AUTOSAR XML (schema 4-3-0)
standard types defined: uint16, uint32, uint8, uint16_DataConstr, uint32_DataConstr, uint8_DataConstr, sint16, boolean, sint32
package /ASP_DataTypes
  48 x impl type:
    accPedalPosition: category=VALUE, base-type=BaseTypes/uint8
    accPedalPositionQual: category=VALUE, base-type=BaseTypes/uint8, compu {0=Cx0_Unsafe, 1=Cx1_Safe, 2=Cx2_SNA; unit Enum}
    brakePedalPressed: category=VALUE, base-type=boolean, compu {0=Cx0_No, 1=Cx1_Yes; unit Enum}
    brakePedalPressedQual: category=VALUE, base-type=BaseTypes/uint8, compu {0=Cx0_Unsafe, 1=Cx1_Safe, 2=Cx2_SNA; unit Enum}
    brakeTorque: category=VALUE, base-type=BaseTypes/uint16
    collAvoidSnvtySetting: category=VALUE, base-type=BaseTypes/uint8, compu {0=Cx0_NotInUse, 1=Cx1_LoSnvty, 2=Cx2_NormSnvty, 3=Cx3_HiSnvty; unit Enum}
    collAvoidSnvtySettingQual: category=VALUE, base-type=BaseTypes/uint8, compu {0=Cx0_Unsafe, 1=Cx1_Safe, 2=Cx2_SNA; unit Enum}
    driverAEBOverride: category=VALUE, base-type=boolean, compu {0=Cx0_No, 1=Cx1_Yes; unit Enum}
    driverAEBOverrideQual: category=VALUE, base-type=BaseTypes/uint8, compu {0=Cx0_Unsafe, 1=Cx1_Safe, 2=Cx2_SNA; unit Enum}
    driverBrakeTorque: category=VALUE, base-type=BaseTypes/uint16
    driverBrakeTorqueQual: category=VALUE, base-type=BaseTypes/uint8, compu {0=Cx0_Unsafe, 1=Cx1_Safe, 2=Cx2_SNA; unit Enum}
    dynamicWheelRadiusFront: category=VALUE, base-type=BaseTypes/uint16
    dynamicWheelRadiusRear: category=VALUE, base-type=BaseTypes/uint16
    EgoMotion_rec: category=STRUCTURE
      20 x element, all with category=TYPE_REFERENCE:
        dynamicWheelRadiusRear: range raw 0..4095, implementation-data-type=dynamicWheelRadiusRear
        lateralAccelerationQual: range raw 0..3, implementation-data-type=lateralAccelerationQual
        lateralAcceleration: range raw -2048..2047, implementation-data-type=lateralAcceleration
        longitudinalSpeedQual: range raw 0..3, implementation-data-type=longitudinalSpeedQual
        wheelSpeedFrontRight: range raw -8192..8191, implementation-data-type=wheelSpeedFrontRight
        dynamicWheelRadiusFront: range raw 0..4095, implementation-data-type=dynamicWheelRadiusFront
        wheelSpeedQual: range raw 0..3, implementation-data-type=wheelSpeedQual
        wheelSpeedFrontLeft: range raw -8192..8191, implementation-data-type=wheelSpeedFrontLeft
        longitudinalSpeed: range raw -8192..8191, implementation-data-type=longitudinalSpeed
        rearWheelAngleQual: range raw 0..3, implementation-data-type=rearWheelAngleQual
        wheelSpeedRearRight: range raw -8192..8191, implementation-data-type=wheelSpeedRearRight
        longitudinalAccelerationQual: range raw 0..3, implementation-data-type=longitudinalAccelerationQual
        frontWheelAngle: range raw -16384..16383, implementation-data-type=frontWheelAngle
        rearWheelAngle: range raw -16384..16383, implementation-data-type=rearWheelAngle
        wheelSpeedRearLeft: range raw -8192..8191, implementation-data-type=wheelSpeedRearLeft
        frontWheelAngleQual: range raw 0..3, implementation-data-type=frontWheelAngleQual
        longitudinalAcceleration: range raw -2048..2047, implementation-data-type=longitudinalAcceleration
        yawRate: implementation-data-type=yawRate
        yawRateQual: range raw 0..3, implementation-data-type=yawRateQual
        brakeTorque: range raw 0..16383, implementation-data-type=brakeTorque
    engineState: category=VALUE, base-type=BaseTypes/uint8, compu {0=Cx0_Stop, 1=Cx1_Start, 2=Cx2_Idle_Unstable (Idle Unstable), 3=Cx3_Idle_Stable (Idle Stable), 4=Cx4_Unlimited, 5=Cx5_Limited, 6=Cx6_SNA; unit Enum}
    frontWheelAngle: category=VALUE, base-type=BaseTypes/sint16
    frontWheelAngleQual: category=VALUE, base-type=BaseTypes/uint8, compu {0=Cx0_Unavailable, 1=Cx1_Available, 2=Cx2_SNA; unit Enum}
    ignitionState: category=VALUE, base-type=BaseTypes/uint8, compu {0=Cx0_Lock, 1=Cx1_OFF, 2=Cx2_ACC, 3=Cx3_ON, 4=Cx4_Start, 5=Cx5_SNA; unit Enum}
    lateralAcceleration: category=VALUE, base-type=BaseTypes/sint16
    lateralAccelerationQual: category=VALUE, base-type=BaseTypes/uint8, compu {0=Cx0_Unavailable, 1=Cx1_Available, 2=Cx2_SNA; unit Enum}
    lateralAccRaw: category=VALUE, base-type=BaseTypes/sint16
    lateralAccRawQual: category=VALUE, base-type=BaseTypes/uint8, compu {0=Cx0_Unsafe, 1=Cx1_Safe, 2=Cx2_SNA; unit Enum}
    longitudinalAcceleration: category=VALUE, base-type=BaseTypes/sint16
    longitudinalAccelerationQual: category=VALUE, base-type=BaseTypes/uint8, compu {0=Cx0_Unavailable, 1=Cx1_Available, 2=Cx2_SNA; unit Enum}
    longitudinalAccRaw: category=VALUE, base-type=BaseTypes/sint16
    longitudinalAccRawQual: category=VALUE, base-type=BaseTypes/uint8, compu {0=Cx0_Unsafe, 1=Cx1_Safe, 2=Cx2_SNA; unit Enum}
    longitudinalSpeed: category=VALUE, base-type=BaseTypes/sint16
    longitudinalSpeedQual: category=VALUE, base-type=BaseTypes/uint8, compu {0=Cx0_Unsafe, 1=Cx1_Safe, 2=Cx2_SNA; unit Enum}
    PositionInfoType: category=STRUCTURE, sw-calibration-access=READ-ONLY, type-emitter=RTE
      element countryCode: category=VALUE, base-type=BaseTypes/uint16, sw-calibration-access=READ-ONLY, invalid-value=1023  # Current country in ISO 3166-1 numerical
    rearWheelAngle: category=VALUE, base-type=BaseTypes/sint16
    rearWheelAngleQual: category=VALUE, base-type=BaseTypes/uint8, compu {0=Cx0_Unavailable, 1=Cx1_Available, 2=Cx2_SNA; unit Enum}
    SG_AEB_Input: category=STRUCTURE
      20 x element, all with category=TYPE_REFERENCE:
        longitudinalAccRaw: range raw -16384..16383, implementation-data-type=longitudinalAccRaw
        steeringWhlAngleSpeedQual: range raw 0..3, implementation-data-type=steeringWhlAngleSpeedQual
        lateralAccRawQual: range raw 0..3, implementation-data-type=lateralAccRawQual
        brakePedalPressed: implementation-data-type=brakePedalPressed
        vehicleMotionState: range raw 0..7, implementation-data-type=vehicleMotionState
        driverBrakeTorqueQual: range raw 0..3, implementation-data-type=driverBrakeTorqueQual
        steeringWhlAngle: range raw -16384..16383, implementation-data-type=steeringWhlAngle
        steeringWhlAngleQual: range raw 0..3, implementation-data-type=steeringWhlAngleQual
        accPedalPositionQual: range raw 0..3, implementation-data-type=accPedalPositionQual
        collAvoidSnvtySetting: range raw 0..3, implementation-data-type=collAvoidSnvtySetting
        longitudinalAccRawQual: range raw 0..3, implementation-data-type=longitudinalAccRawQual
        steeringWhlAngleSpeed: range raw -65536..65535, implementation-data-type=steeringWhlAngleSpeed
        driverAEBOverrideQual: range raw 0..3, implementation-data-type=driverAEBOverrideQual
        collAvoidSnvtySettingQual: range raw 0..3, implementation-data-type=collAvoidSnvtySettingQual
        driverAEBOverride: implementation-data-type=driverAEBOverride
        accPedalPosition: range raw 0..100, implementation-data-type=accPedalPosition
        vehicleMotionStateQual: range raw 0..3, implementation-data-type=vehicleMotionStateQual
        driverBrakeTorque: range raw 0..20000, implementation-data-type=driverBrakeTorque
        brakePedalPressedQual: range raw 0..3, implementation-data-type=brakePedalPressedQual
        lateralAccRaw: range raw -16384..16383, implementation-data-type=lateralAccRaw
    steeringWhlAngle: category=VALUE, base-type=BaseTypes/sint16
    steeringWhlAngleQual: category=VALUE, base-type=BaseTypes/uint8, compu {0=Cx0_Unsafe, 1=Cx1_Safe, 2=Cx2_SNA; unit Enum}
    steeringWhlAngleSpeed: category=VALUE, base-type=sint32
    steeringWhlAngleSpeedQual: category=VALUE, base-type=BaseTypes/uint8, compu {0=Cx0_Unsafe, 1=Cx1_Safe, 2=Cx2_SNA; unit Enum}
    suspensionType: category=VALUE, base-type=BaseTypes/uint8
    turnIndicator: category=VALUE, base-type=BaseTypes/uint8
    VehicleMisc_rec: category=STRUCTURE
      4 x element, all with category=TYPE_REFERENCE, range raw 0..7:
        suspensionType: implementation-data-type=suspensionType
        ignitionState: implementation-data-type=ignitionState
        turnIndicator: implementation-data-type=turnIndicator
        engineState: implementation-data-type=engineState
    vehicleMotionState: category=VALUE, base-type=BaseTypes/uint8, compu {0=Cx0_Ukwn, 1=Cx1_StandStillVal1, 2=Cx2_StandStillVal2, 3=Cx3_StandStillVal3, 4=Cx4_RollgFwdVal1, 5=Cx5_RollgFwdVal2, 6=Cx6_RollgBackwVal1, 7=Cx7_RollgBackwVal2; unit Enum}
    vehicleMotionStateQual: category=VALUE, base-type=BaseTypes/uint8, compu {0=Cx0_Unsafe, 1=Cx1_Safe, 2=Cx2_SNA; unit Enum}
    wheelSpeedFrontLeft: category=VALUE, base-type=BaseTypes/sint16
    wheelSpeedFrontRight: category=VALUE, base-type=BaseTypes/sint16
    wheelSpeedQual: category=VALUE, base-type=BaseTypes/uint8, compu {0=Cx0_Unavailable, 1=Cx1_Available, 2=Cx2_SNA; unit Enum}
    wheelSpeedRearLeft: category=VALUE, base-type=BaseTypes/sint16
    wheelSpeedRearRight: category=VALUE, base-type=BaseTypes/sint16
    yawRate: category=VALUE, base-type=BaseTypes/sint16
    yawRateQual: category=VALUE, base-type=BaseTypes/uint8, compu {0=Cx0_Unavailable, 1=Cx1_Available, 2=Cx2_SNA; unit Enum}
package /ASP_DataTypes/Units
  unit U_Enum: display-name=Enum, factor-si-to-unit=1, offset-si-to-unit=0
package /ASP_PortInterfaces
  sender receiver interface CddGvpSRVehicleInputInterface
    data EgoMotionElement: type=EgoMotion_rec
    data PositionInfo: type=PositionInfoType
    data VehicleMiscElement: type=VehicleMisc_rec
    invalidation-policys:
      data-element=EgoMotionElement, handle-invalid=DONT-INVALIDATE
      data-element=VehicleMiscElement, handle-invalid=DONT-INVALIDATE
      data-element=PositionInfo, handle-invalid=DONT-INVALIDATE
  sender receiver interface SG_AEB_Input: invalidation-policy{data-element=SG_AEB_Input, handle-invalid=DONT-INVALIDATE}
    data SG_AEB_Input: type=SG_AEB_Input
package /ComponentTypes/HkmcRadarAdapSWC/Constants
  constant specification CS_RadarAdap_Radar: value-spec=fields=[SAS_AnglVal:0, ESC_YawRtVal:0, ESC_LatAccelVal:0, ESC_LongAccelVal:0, longitudinalSpeed:0, longitudinalSpeedQual:0, WHL_DirFLVal:0, WHL_DirFRVal:0, WHL_DirRLVal:0, WHL_DirRRVal:0, ENG_EngSta:0, HCU_HevRdySta:0, VCU_EVRdySta:0, ENG_IgnOnSta:0, CLU_OdoVal:0]
package /ComponentTypes/HkmcRadarAdapSWC/DataTypes
  impl type Radar_T: category=STRUCTURE, sw-calibration-access=READ-ONLY, type-emitter=RTE
    15 x element, all with category=TYPE_REFERENCE:
      SAS_AnglVal: implementation-data-type=uint8
      ESC_YawRtVal: implementation-data-type=uint8
      ESC_LatAccelVal: implementation-data-type=uint8
      ESC_LongAccelVal: implementation-data-type=uint16
      longitudinalSpeed: implementation-data-type=uint8
      longitudinalSpeedQual: implementation-data-type=uint8
      WHL_DirFLVal: implementation-data-type=uint8
      WHL_DirFRVal: implementation-data-type=uint8
      WHL_DirRLVal: implementation-data-type=uint8
      WHL_DirRRVal: implementation-data-type=uint8
      ENG_EngSta: implementation-data-type=uint8
      HCU_HevRdySta: implementation-data-type=uint8
      VCU_EVRdySta: implementation-data-type=uint8
      ENG_IgnOnSta: implementation-data-type=uint8
      CLU_OdoVal: implementation-data-type=uint32
package /ComponentTypes/HkmcRadarAdapSWC/PortInterfaces
  sender receiver interface IF_Radar: invalidation-policy{data-element=DE_HkmcRadarAdapInput, handle-invalid=DONT-INVALIDATE}
    data DE_HkmcRadarAdapInput: type=Radar_T
package /ComponentTypes/HkmcVehicleInputSWC
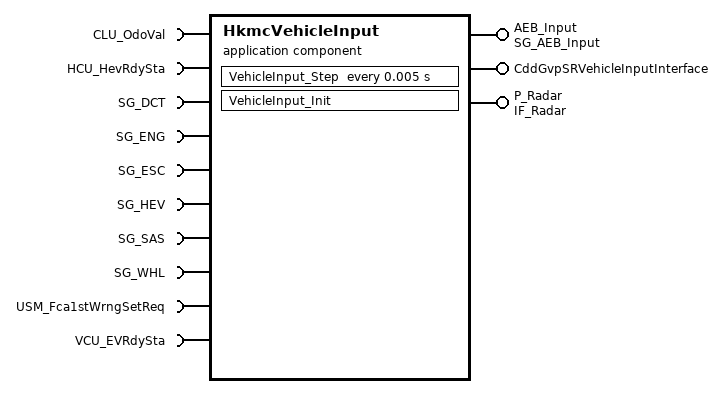
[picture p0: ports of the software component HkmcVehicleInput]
  application sw component type HkmcVehicleInput
    provide port AEB_Input: nonqueued-sender-com-spec{data-element=SG_AEB_Input, init-value=fields=[longitudinalAccRaw:0, steeringWhlAngleSpeedQual:0, lateralAccRawQual:0, brakePedalPressed:0, vehicleMotionState:0, driverBrakeTorqueQual:0, steeringWhlAngle:0, steeringWhlAngleQual:0, accPedalPositionQual:0, collAvoidSnvtySetting:0, longitudinalAccRawQual:0, steeringWhlAngleSpeed:0, driverAEBOverrideQual:0, collAvoidSnvtySettingQual:0, driverAEBOverride:0, accPedalPosition:0, vehicleMotionStateQual:0, driverBrakeTorque:0, brakePedalPressedQual:0, lateralAccRaw:0]}, provided-interface=SG_AEB_Input
    provide port CddGvpSRVehicleInputInterface: provided-com-specs=[data-element=EgoMotionElement, data-element=PositionInfo, data-element=VehicleMiscElement], provided-interface=CddGvpSRVehicleInputInterface
    provide port P_Radar: nonqueued-sender-com-spec{data-element=DE_HkmcRadarAdapInput, init-value=constant-reference=CS_RadarAdap_Radar}, provided-interface=IF_Radar
    10 x require port:
      CLU_OdoVal: nonqueued-receiver-com-spec{data-element=CLU_OdoVal, filter=data-filter-type=ALWAYS, init-value=0}, required-interface=CLU_OdoVal
      HCU_HevRdySta: nonqueued-receiver-com-spec{data-element=HCU_HevRdySta, filter=data-filter-type=ALWAYS, init-value=0}, required-interface=HCU_HevRdySta
      SG_DCT: nonqueued-receiver-com-spec{data-element=SG_DCT, filter=data-filter-type=ALWAYS, init-value=fields=DCT_AccelPdlVal:0}, required-interface=SG_DCT
      SG_ENG: nonqueued-receiver-com-spec{data-element=SG_ENG, filter=data-filter-type=ALWAYS, init-value=fields=ENG_IgnOnSta:1}, required-interface=SG_ENG
      SG_ESC: nonqueued-receiver-com-spec{data-element=SG_ESC, filter=data-filter-type=ALWAYS, init-value=fields=[ESC_LatAccelSigSta:2, ESC_LatAccelVal:32768, ESC_LongAccelSigSta:2, ESC_LongAccelVal:32768, ESC_YawRtVal:32768, ESC_YawSigSta:2]}, required-interface=SG_ESC
      SG_HEV: nonqueued-receiver-com-spec{data-element=SG_HEV, filter=data-filter-type=ALWAYS, init-value=fields=[HEV_AccelPdlVal:0, HEV_EngSpdVal:0]}, required-interface=SG_HEV
      SG_SAS: nonqueued-receiver-com-spec{data-element=SG_SAS, filter=data-filter-type=ALWAYS, init-value=fields=[SAS_AlvCnt1Val:0, SAS_AnglVal:0, SAS_Crc1Val:65535, SAS_IntSta:7, SAS_SpdVal:0]}, required-interface=SG_SAS
      SG_WHL: nonqueued-receiver-com-spec{data-element=SG_WHL, filter=data-filter-type=ALWAYS, init-value=fields=[WHL_DirRRVal:0, WHL_SpdFLVal:0, WHL_SpdFRVal:0, WHL_SpdRLVal:0, WHL_SpdRRVal:0]}, required-interface=SG_WHL
      USM_Fca1stWrngSetReq: nonqueued-receiver-com-spec{data-element=USM_Fca1stWrngSetReq, filter=data-filter-type=ALWAYS, init-value=0}, required-interface=USM_Fca1stWrngSetReq
      VCU_EVRdySta: nonqueued-receiver-com-spec{data-element=VCU_EVRdySta, filter=data-filter-type=ALWAYS, init-value=0}, required-interface=VCU_EVRdySta
    behavior HkmcVehicleInput_InternalBehavior
      init event VehicleInput_InitEvent: start-on-event=VehicleInput_Init
      timing event VehicleInput_Step_TE: start-on-event=VehicleInput_Step, period=0.005
      runnable VehicleInput_Init
        data-receive-point-by-arguments:
          10 x access:
            REC_CLU_OdoVal_CLU_OdoVal: accessed-variable=CLU_OdoVal.CLU_OdoVal
            REC_HCU_HevRdySta_HCU_HevRdySta: accessed-variable=HCU_HevRdySta.HCU_HevRdySta
            REC_SG_DCT_SG_DCT: accessed-variable=SG_DCT.SG_DCT
            REC_SG_ENG_SG_ENG: accessed-variable=SG_ENG.SG_ENG
            REC_SG_ESC_SG_ESC: accessed-variable=SG_ESC.SG_ESC
            REC_SG_HEV_SG_HEV: accessed-variable=SG_HEV.SG_HEV
            REC_SG_SAS_SG_SAS: accessed-variable=SG_SAS.SG_SAS
            REC_SG_WHL_SG_WHL: accessed-variable=SG_WHL.SG_WHL
            REC_USM_Fca1stWrngSetReq_USM_Fca1stWrngSetReq: accessed-variable=USM_Fca1stWrngSetReq.USM_Fca1stWrngSetReq
            REC_VCU_EVRdySta_VCU_EVRdySta: accessed-variable=VCU_EVRdySta.VCU_EVRdySta
        data-send-points:
          5 x access:
            SEND_AEB_Input_SG_AEB_Input: accessed-variable=AEB_Input.SG_AEB_Input
            SEND_CddGvpSRVehicleInputInterface_EgoMotionElement: accessed-variable=CddGvpSRVehicleInputInterface.EgoMotionElement
            SEND_CddGvpSRVehicleInputInterface_PositionInfo: accessed-variable=CddGvpSRVehicleInputInterface.PositionInfo
            SEND_CddGvpSRVehicleInputInterface_VehicleMiscElement: accessed-variable=CddGvpSRVehicleInputInterface.VehicleMiscElement
            SEND_P_Radar_DE_HkmcRadarAdapInput: accessed-variable=P_Radar.DE_HkmcRadarAdapInput
      runnable VehicleInput_Step
        data-receive-point-by-arguments:
          10 x access:
            REC_CLU_OdoVal_CLU_OdoVal: accessed-variable=CLU_OdoVal.CLU_OdoVal
            REC_HCU_HevRdySta_HCU_HevRdySta: accessed-variable=HCU_HevRdySta.HCU_HevRdySta
            REC_SG_DCT_SG_DCT: accessed-variable=SG_DCT.SG_DCT
            REC_SG_ENG_SG_ENG: accessed-variable=SG_ENG.SG_ENG
            REC_SG_ESC_SG_ESC: accessed-variable=SG_ESC.SG_ESC
            REC_SG_HEV_SG_HEV: accessed-variable=SG_HEV.SG_HEV
            REC_SG_SAS_SG_SAS: accessed-variable=SG_SAS.SG_SAS
            REC_SG_WHL_SG_WHL: accessed-variable=SG_WHL.SG_WHL
            REC_USM_Fca1stWrngSetReq_USM_Fca1stWrngSetReq: accessed-variable=USM_Fca1stWrngSetReq.USM_Fca1stWrngSetReq
            REC_VCU_EVRdySta_VCU_EVRdySta: accessed-variable=VCU_EVRdySta.VCU_EVRdySta
        data-send-points:
          5 x access:
            SEND_AEB_Input_SG_AEB_Input: accessed-variable=AEB_Input.SG_AEB_Input
            SEND_CddGvpSRVehicleInputInterface_EgoMotionElement: accessed-variable=CddGvpSRVehicleInputInterface.EgoMotionElement
            SEND_CddGvpSRVehicleInputInterface_PositionInfo: accessed-variable=CddGvpSRVehicleInputInterface.PositionInfo
            SEND_CddGvpSRVehicleInputInterface_VehicleMiscElement: accessed-variable=CddGvpSRVehicleInputInterface.VehicleMiscElement
            SEND_P_Radar_DE_HkmcRadarAdapInput: accessed-variable=P_Radar.DE_HkmcRadarAdapInput
  swc implementation HkmcVehicleInput_Implementation: behavior=HkmcVehicleInput_InternalBehavior
    code-descriptors:
      code Default: artifact-descriptors=autosar-engineering-object={short-label=Default, category=SWSRC}
package /DataTypes
  30 x impl type:
    CLU_OdoVal: category=VALUE, base-type=DataType/uint32, range raw 0..16777215
    DCT_AccelPdlVal: category=VALUE, base-type=DataType/uint16
    ENG_IgnOnSta: category=VALUE, base-type=DataType/uint8, compu {0=Cx0_KEY_OFF_control_unit_in_self_holding_phase (KEY OFF, control unit in self-holding phase), 1=Cx1_KEY_ON (KEY ON), 2=Cx2_Not_used (Not used), 3=Cx3_Error_indicator (Error indicator)}
    ESC_LatAccelSigSta: category=VALUE, base-type=DataType/uint8
    ESC_LatAccelVal: category=VALUE, base-type=DataType/uint16
    ESC_LongAccelSigSta: category=VALUE, base-type=DataType/uint8
    ESC_LongAccelVal: category=VALUE, base-type=DataType/uint16
    ESC_YawRtVal: category=VALUE, base-type=DataType/uint16
    ESC_YawSigSta: category=VALUE, base-type=DataType/uint8
    HCU_HevRdySta: category=VALUE, base-type=DataType/uint8, compu {0=Cx0_HEV_not_ready (HEV not ready), 1=Cx1_HEV_Drivable (HEV Drivable), 2=Cx2_Not_used (Not used), 3=Cx3_Error_Indicator (Error Indicator)}, range raw 0..3
    HEV_AccelPdlVal: category=VALUE, base-type=DataType/uint16
    HEV_EngSpdVal: category=VALUE, base-type=DataType/uint16
    SAS_AlvCnt1Val: category=VALUE, base-type=DataType/uint8
    SAS_AnglVal: category=VALUE, base-type=DataType/sint16
    SAS_Crc1Val: category=VALUE, base-type=DataType/uint16
    SAS_IntSta: category=VALUE, base-type=DataType/uint8
    SAS_SpdVal: category=VALUE, base-type=DataType/uint8
    SG_DCT: category=STRUCTURE
      element DCT_AccelPdlVal: range raw 0..1023, implementation-data-type=DCT_AccelPdlVal
    SG_ENG: category=STRUCTURE
      element ENG_IgnOnSta: range raw 0..3, implementation-data-type=ENG_IgnOnSta
    SG_ESC: category=STRUCTURE
      6 x element, all with category=TYPE_REFERENCE:
        ESC_LatAccelSigSta: range raw 0..15, implementation-data-type=ESC_LatAccelSigSta
        ESC_LatAccelVal: implementation-data-type=ESC_LatAccelVal
        ESC_LongAccelSigSta: range raw 0..15, implementation-data-type=ESC_LongAccelSigSta
        ESC_LongAccelVal: implementation-data-type=ESC_LongAccelVal
        ESC_YawRtVal: implementation-data-type=ESC_YawRtVal
        ESC_YawSigSta: range raw 0..15, implementation-data-type=ESC_YawSigSta
    SG_HEV: category=STRUCTURE
      element HEV_AccelPdlVal: range raw 0..1023, implementation-data-type=HEV_AccelPdlVal
      element HEV_EngSpdVal: implementation-data-type=HEV_EngSpdVal
    SG_SAS: category=STRUCTURE
      5 x element, all with category=TYPE_REFERENCE:
        SAS_AlvCnt1Val: range raw 0..255, implementation-data-type=SAS_AlvCnt1Val
        SAS_AnglVal: implementation-data-type=SAS_AnglVal
        SAS_Crc1Val: range raw 0..65535, implementation-data-type=SAS_Crc1Val
        SAS_IntSta: range raw 0..255, implementation-data-type=SAS_IntSta
        SAS_SpdVal: implementation-data-type=SAS_SpdVal
    SG_WHL: category=STRUCTURE
      5 x element, all with category=TYPE_REFERENCE:
        WHL_DirRRVal: range raw 0..3, implementation-data-type=WHL_DirRRVal
        WHL_SpdFLVal: range raw 0..16383, implementation-data-type=WHL_SpdFLVal
        WHL_SpdFRVal: range raw 0..16383, implementation-data-type=WHL_SpdFRVal
        WHL_SpdRLVal: range raw 0..16383, implementation-data-type=WHL_SpdRLVal
        WHL_SpdRRVal: range raw 0..16383, implementation-data-type=WHL_SpdRRVal
    USM_Fca1stWrngSetReq: category=VALUE, base-type=DataType/uint8, compu {0=Cx0_Default, 1=Cx1_On_Late_ (On (Late)), 2=Cx2_ON_Normal_ (ON (Normal)), 3=Cx3_ON_Early_ (ON (Early)), 4=Cx4_Reserved, 5=Cx5_Reserved, 6=Cx6_Reserved, 7=Cx7_Invalid}, range raw 0..7
    VCU_EVRdySta: category=VALUE, base-type=DataType/uint8, compu {0=Cx0_None, 1=Cx1_EV_Drivable (EV Drivable), 2=Cx2_Not_used (Not used), 3=Cx3_Error_Indicator (Error Indicator)}, range raw 0..3
    WHL_DirRRVal: category=VALUE, base-type=DataType/uint8, compu {0=Cx0_Unknown_Wheel_moving_stop_state_or_Not_applied_wheel_sensor_for_direction_ (Unknown (Wheel moving stop state or Not applied wheel sensor for direction)), 1=Cx1_Forward_direction (Forward direction), 2=Cx2_Backward_direction (Backward direction), 3=Cx3_Error_identifier (Error identifier)}
    WHL_SpdFLVal: category=VALUE, base-type=DataType/uint16
    WHL_SpdFRVal: category=VALUE, base-type=DataType/uint16
    WHL_SpdRLVal: category=VALUE, base-type=DataType/uint16
    WHL_SpdRRVal: category=VALUE, base-type=DataType/uint16
package /PortInterfaces
  10 x sender receiver interface:
    CLU_OdoVal: invalidation-policy{data-element=CLU_OdoVal, handle-invalid=DONT-INVALIDATE}
      data CLU_OdoVal: type=CLU_OdoVal
    HCU_HevRdySta: invalidation-policy{data-element=HCU_HevRdySta, handle-invalid=DONT-INVALIDATE}
      data HCU_HevRdySta: type=HCU_HevRdySta
    SG_DCT: invalidation-policy{data-element=SG_DCT, handle-invalid=DONT-INVALIDATE}
      data SG_DCT: type=SG_DCT
    SG_ENG: invalidation-policy{data-element=SG_ENG, handle-invalid=DONT-INVALIDATE}
      data SG_ENG: type=SG_ENG
    SG_ESC: invalidation-policy{data-element=SG_ESC, handle-invalid=DONT-INVALIDATE}
      data SG_ESC: type=SG_ESC
    SG_HEV: invalidation-policy{data-element=SG_HEV, handle-invalid=DONT-INVALIDATE}
      data SG_HEV: type=SG_HEV
    SG_SAS: invalidation-policy{data-element=SG_SAS, handle-invalid=DONT-INVALIDATE}
      data SG_SAS: type=SG_SAS
    SG_WHL: invalidation-policy{data-element=SG_WHL, handle-invalid=DONT-INVALIDATE}
      data SG_WHL: type=SG_WHL
    USM_Fca1stWrngSetReq: invalidation-policy{data-element=USM_Fca1stWrngSetReq, handle-invalid=DONT-INVALIDATE}
      data USM_Fca1stWrngSetReq: type=USM_Fca1stWrngSetReq
    VCU_EVRdySta: invalidation-policy{data-element=VCU_EVRdySta, handle-invalid=DONT-INVALIDATE}
      data VCU_EVRdySta: type=VCU_EVRdySta
